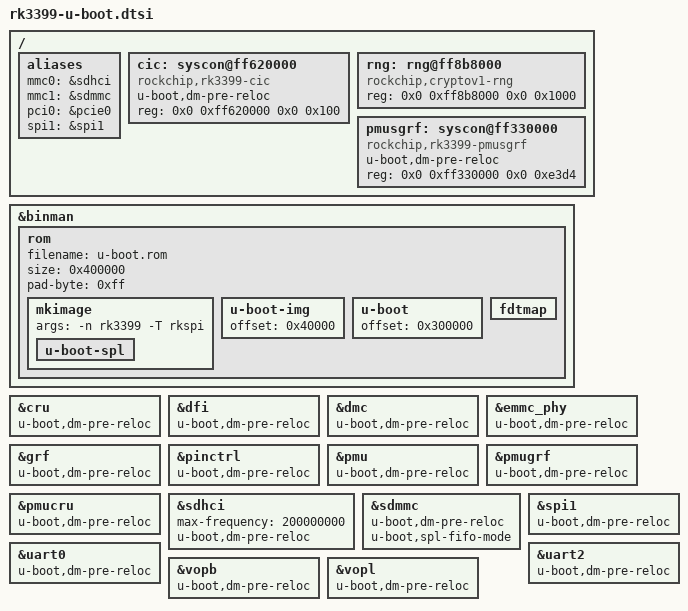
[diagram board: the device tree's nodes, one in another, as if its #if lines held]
// SPDX-License-Identifier: GPL-2.0+
/*
 * Copyright (C) 2019 Jagan Teki <jagan@amarulasolutions.com>
 */
#define USB_CLASS_HUB			9

#include "rockchip-u-boot.dtsi"

/ {
	aliases {
		mmc0 = &sdhci;
		mmc1 = &sdmmc;
		pci0 = &pcie0;
		spi1 = &spi1;
	};

	cic: syscon@ff620000 {
		u-boot,dm-pre-reloc;
		compatible = "rockchip,rk3399-cic", "syscon";
		reg = <0x0 0xff620000 0x0 0x100>;
	};

	rng: rng@ff8b8000 {
		compatible = "rockchip,cryptov1-rng";
		reg = <0x0 0xff8b8000 0x0 0x1000>;
		status = "okay";
	};

	pmusgrf: syscon@ff330000 {
		u-boot,dm-pre-reloc;
		compatible = "rockchip,rk3399-pmusgrf", "syscon";
		reg = <0x0 0xff330000 0x0 0xe3d4>;
	};

};

#if defined(CONFIG_ROCKCHIP_SPI_IMAGE) && defined(CONFIG_HAS_ROM)
&binman {
	rom {
		filename = "u-boot.rom";
		size = <0x400000>;
		pad-byte = <0xff>;

		mkimage {
			args = "-n rk3399 -T rkspi";
			u-boot-spl {
			};
		};
		u-boot-img {
			offset = <0x40000>;
		};
		u-boot {
			offset = <0x300000>;
		};
		fdtmap {
		};
	};
};
#endif

&cru {
	u-boot,dm-pre-reloc;
};

&dfi {
	u-boot,dm-pre-reloc;
	status = "okay";
};

&dmc {
	u-boot,dm-pre-reloc;
	status = "okay";
};

&emmc_phy {
	u-boot,dm-pre-reloc;
};

&grf {
	u-boot,dm-pre-reloc;
};

&pinctrl {
	u-boot,dm-pre-reloc;
};

&pmu {
	u-boot,dm-pre-reloc;
};

&pmugrf {
	u-boot,dm-pre-reloc;
};

&pmu {
	u-boot,dm-pre-reloc;
};

&pmucru {
	u-boot,dm-pre-reloc;
};

&sdhci {
	max-frequency = <200000000>;
	u-boot,dm-pre-reloc;
};

&sdmmc {
	u-boot,dm-pre-reloc;

	/* mmc to sram can't do dma, prevent aborts transferring TF-A parts */
	u-boot,spl-fifo-mode;
};

&spi1 {
	u-boot,dm-pre-reloc;
};

&uart0 {
	u-boot,dm-pre-reloc;
};

&uart2 {
	u-boot,dm-pre-reloc;
};

&vopb {
	u-boot,dm-pre-reloc;
};

&vopl {
	u-boot,dm-pre-reloc;
};
